VERSION ""

NS_ :

BS_:

BU_: BAP_Tester BedienDisp_vo BedienSG_hi CGS DDA Gateway Gateway_PAG GurtMikrofon OTA_FC ZR_High ZR_LIMU ZR_MIB_TOP_ab_Gen3 ZR_Standard

BO_ 870 Blinkmodi_02: 8 Gateway
 SG_ BM_ZV_auf : 12|1@1+ (1.0,0.0) [0.0|1] ""  ZR_High
 SG_ BM_ZV_zu : 13|1@1+ (1.0,0.0) [0.0|1] ""  ZR_High
 SG_ BM_DWA_ein : 14|1@1+ (1.0,0.0) [0.0|1] ""  ZR_High
 SG_ BM_DWA_Alarm : 15|1@1+ (1.0,0.0) [0.0|1] ""  ZR_High
 SG_ BM_Crash : 16|1@1+ (1.0,0.0) [0.0|1] ""  ZR_High
 SG_ BM_Panik : 17|1@1+ (1.0,0.0) [0.0|1] ""  ZR_High
 SG_ BM_Not_Bremsung : 18|1@1+ (1.0,0.0) [0.0|1] ""  ZR_High
 SG_ BM_GDO : 19|1@1+ (1.0,0.0) [0.0|1] ""  Vector__XXX
 SG_ BM_Warnblinken : 20|1@1+ (1.0,0.0) [0.0|1] ""  ZR_High
 SG_ BM_Taxi_Notalarm : 21|1@1+ (1.0,0.0) [0.0|1] ""  ZR_High
 SG_ BM_Telematik : 22|1@1+ (1.0,0.0) [0.0|1] ""  ZR_High
 SG_ BM_links : 23|1@1+ (1.0,0.0) [0.0|1] ""  ZR_High
 SG_ BM_rechts : 24|1@1+ (1.0,0.0) [0.0|1] ""  ZR_High
 SG_ Blinken_li_Fzg_Takt : 25|1@1+ (1.0,0.0) [0.0|1] ""  ZR_High
 SG_ Blinken_re_Fzg_Takt : 26|1@1+ (1.0,0.0) [0.0|1] ""  ZR_High
 SG_ Blinken_li_Kombi_Takt : 27|1@1+ (1.0,0.0) [0.0|1] ""  ZR_High,ZR_LIMU,ZR_MIB_TOP_ab_Gen3,ZR_Standard
 SG_ Blinken_re_Kombi_Takt : 28|1@1+ (1.0,0.0) [0.0|1] ""  ZR_High,ZR_LIMU,ZR_MIB_TOP_ab_Gen3,ZR_Standard
 SG_ BM_NBA_n_codiert_n_aktiv : 29|1@1+ (1.0,0.0) [0.0|1] ""  Vector__XXX
 SG_ BM_NBA_Status : 30|2@1+ (1.0,0.0) [0.0|3] ""  Vector__XXX
 SG_ BM_WBT_Beleuchtung : 32|1@1+ (1.0,0.0) [0.0|1] ""  ZR_High
 SG_ BM_HD_Oeffnung_angelernt : 33|1@1+ (1.0,0.0) [0.0|1] ""  Vector__XXX
 SG_ BM_Autobahn : 34|1@1+ (1.0,0.0) [0.0|1] ""  ZR_High,ZR_LIMU,ZR_MIB_TOP_ab_Gen3
 SG_ BM_Rollenmodus_Blinken : 35|1@1+ (1.0,0.0) [0.0|1] ""  Vector__XXX
 SG_ BM_Recas : 36|1@1+ (1.0,0.0) [0.0|1] ""  ZR_High
 SG_ BM_Wischblinken : 37|1@1+ (1.0,0.0) [0.0|1] ""  ZR_High
 SG_ BM_Telematik_Abbruchgrund : 38|6@1+ (1.0,0.0) [0.0|63] ""  Vector__XXX
 SG_ BM_PiloPa : 44|1@1+ (1.0,0.0) [0.0|1] ""  ZR_High
 SG_ DWA_Alarmquelle : 59|5@1+ (1.0,0.0) [0.0|31] ""  ZR_High

BO_ 299 GRA_ACC_01: 8 Gateway
 SG_ CHECKSUM : 0|8@1+ (1,0) [0|255] ""  Vector__XXX
 SG_ COUNTER : 8|4@1+ (1,0) [0|15] ""  Vector__XXX
 SG_ GRA_Hauptschalter : 12|1@1+ (1.0,0.0) [0.0|1] ""  ZR_High
 SG_ GRA_Abbrechen : 13|1@1+ (1.0,0.0) [0.0|1] ""  ZR_High
 SG_ GRA_Typ_Hauptschalter : 14|1@1+ (1.0,0.0) [0.0|1] ""  ZR_High
 SG_ GRA_Limiter : 15|1@1+ (1.0,0.0) [0.0|1] ""  ZR_High
 SG_ GRA_Tip_Setzen : 16|1@1+ (1.0,0.0) [0.0|1] ""  ZR_High
 SG_ GRA_Tip_Hoch : 17|1@1+ (1.0,0.0) [0.0|1] ""  ZR_High
 SG_ GRA_Tip_Runter : 18|1@1+ (1.0,0.0) [0.0|1] ""  ZR_High
 SG_ GRA_Tip_Wiederaufnahme : 19|1@1+ (1.0,0.0) [0.0|1] ""  ZR_High
 SG_ GRA_Verstellung_Zeitluecke : 20|2@1+ (1.0,0.0) [0.0|3] ""  ZR_High
 SG_ GRA_Codierung : 22|2@1+ (1.0,0.0) [0.0|3] ""  ZR_High
 SG_ GRA_Fehler : 24|1@1+ (1.0,0.0) [0.0|1] ""  ZR_High
 SG_ GRA_LIM_Taste_verfuegbar : 25|1@1+ (1.0,0.0) [0.0|1] ""  ZR_High
 SG_ GRA_Tip_Stufe_2 : 26|1@1+ (1.0,0.0) [0.0|1] ""  ZR_High
 SG_ GRA_Typ_Bedienteil : 27|3@1+ (1.0,0.0) [0.0|7] ""  ZR_High
 SG_ GRA_TravelAssist : 30|1@1+ (1.0,0.0) [0.0|1] ""  Vector__XXX
 SG_ GRA_reserveByte4 : 31|1@1+ (1.0,0.0) [0.0|1] ""  Vector__XXX
 SG_ GRA_reserveByte5 : 32|8@1+ (1.0,0.0) [0.0|255] ""  Vector__XXX
 SG_ GRA_reserveByte6 : 40|8@1+ (1.0,0.0) [0.0|255] ""  Vector__XXX
 SG_ GRA_reserveByte7 : 48|8@1+ (1.0,0.0) [0.0|255] ""  Vector__XXX
 SG_ GRA_reserveByte8 : 56|8@1+ (1.0,0.0) [0.0|255] ""  Vector__XXX

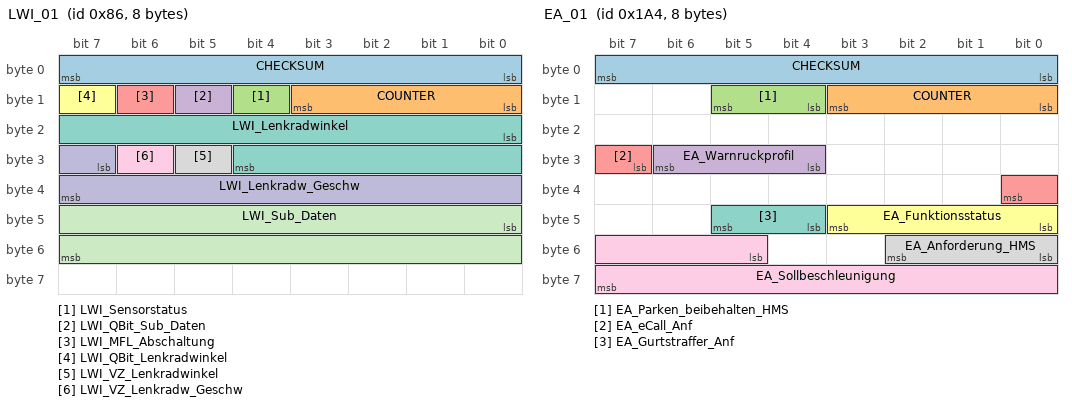
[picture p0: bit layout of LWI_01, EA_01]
BO_ 134 LWI_01: 8 Gateway
 SG_ CHECKSUM : 0|8@1+ (1,0) [0|255] ""  Vector__XXX
 SG_ COUNTER : 8|4@1+ (1,0) [0|15] ""  Vector__XXX
 SG_ LWI_Sensorstatus : 12|1@1+ (1.0,0.0) [0.0|1] ""  ZR_High,ZR_LIMU,ZR_MIB_TOP_ab_Gen3,ZR_Standard
 SG_ LWI_QBit_Sub_Daten : 13|1@1+ (1.0,0.0) [0.0|1] ""  ZR_High
 SG_ LWI_MFL_Abschaltung : 14|1@1+ (1.0,0.0) [0.0|1] ""  ZR_High
 SG_ LWI_QBit_Lenkradwinkel : 15|1@1+ (1.0,0.0) [0.0|1] ""  ZR_High,ZR_LIMU,ZR_MIB_TOP_ab_Gen3,ZR_Standard
 SG_ LWI_Lenkradwinkel : 16|13@1+ (0.1,0) [0.0|800.0] "Unit_DegreOfArc"  OTA_FC,ZR_High,ZR_LIMU,ZR_MIB_TOP_ab_Gen3,ZR_Standard
 SG_ LWI_VZ_Lenkradwinkel : 29|1@1+ (1.0,0.0) [0.0|1] ""  OTA_FC,ZR_High,ZR_LIMU,ZR_MIB_TOP_ab_Gen3,ZR_Standard
 SG_ LWI_VZ_Lenkradw_Geschw : 30|1@1+ (1.0,0.0) [0.0|1] ""  ZR_High
 SG_ LWI_Lenkradw_Geschw : 31|9@1+ (5,0) [0|2500] "Unit_DegreOfArcPerSecon"  OTA_FC,ZR_High
 SG_ LWI_Sub_Daten : 40|16@1+ (1,0) [0|65535] ""  Vector__XXX

BO_ 420 EA_01: 8 Gateway
 SG_ CHECKSUM : 0|8@1+ (1,0) [0|255] ""  Vector__XXX
 SG_ COUNTER : 8|4@1+ (1,0) [0|15] ""  Vector__XXX
 SG_ EA_Parken_beibehalten_HMS : 12|2@1+ (1.0,0.0) [0.0|3] ""  Vector__XXX
 SG_ EA_Warnruckprofil : 28|3@1+ (1.0,0.0) [0.0|7] ""  Vector__XXX
 SG_ EA_eCall_Anf : 31|2@1+ (1.0,0.0) [0.0|3] ""  ZR_High
 SG_ EA_Funktionsstatus : 40|4@1+ (1.0,0.0) [0.0|15] ""  ZR_High
 SG_ EA_Gurtstraffer_Anf : 44|2@1+ (1.0,0.0) [0.0|3] ""  Vector__XXX
 SG_ EA_Anforderung_HMS : 48|3@1+ (1.0,0.0) [0.0|7] ""  Vector__XXX
 SG_ EA_Sollbeschleunigung : 53|11@1+ (0.005,-7.22) [-7.220|3.005] "Unit_MeterPerSeconSquar"  Vector__XXX

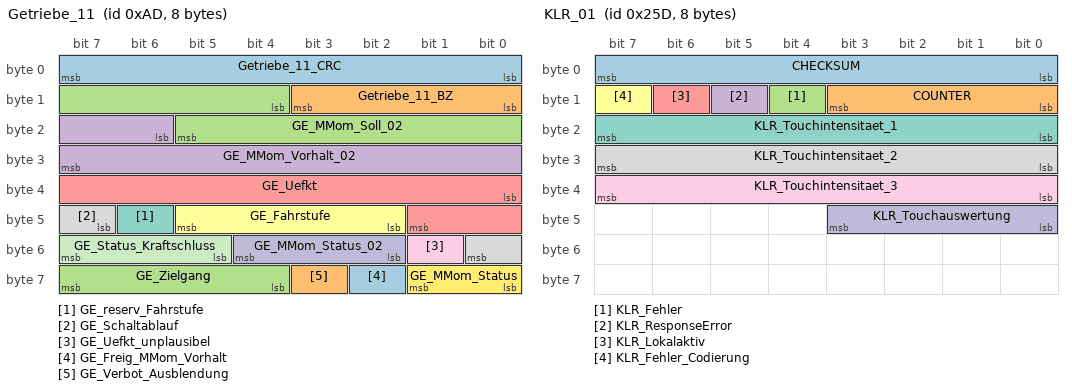
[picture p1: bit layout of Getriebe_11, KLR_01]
BO_ 173 Getriebe_11: 8 Gateway
 SG_ Getriebe_11_CRC : 0|8@1+ (1,0) [0|255] ""  Vector__XXX
 SG_ Getriebe_11_BZ : 8|4@1+ (1,0) [0|15] ""  Vector__XXX
 SG_ GE_MMom_Soll_02 : 12|10@1+ (1,-509) [-509|509] ""  Vector__XXX
 SG_ GE_MMom_Vorhalt_02 : 22|10@1+ (1,-509) [-509|509] ""  Vector__XXX
 SG_ GE_Uefkt : 32|10@1+ (0.1,0) [0.0|102.2] ""  Vector__XXX
 SG_ GE_Fahrstufe : 42|4@1+ (1.0,0.0) [0.0|15] ""  DDA,OTA_FC,ZR_High,ZR_LIMU,ZR_MIB_TOP_ab_Gen3
 SG_ GE_reserv_Fahrstufe : 46|1@1+ (1,0) [0|1] ""  Vector__XXX
 SG_ GE_Schaltablauf : 47|2@1+ (1.0,0.0) [0.0|3] ""  Vector__XXX
 SG_ GE_Uefkt_unplausibel : 49|1@1+ (1.0,0.0) [0.0|1] ""  Vector__XXX
 SG_ GE_MMom_Status_02 : 50|3@1+ (1.0,0.0) [0.0|7] ""  Vector__XXX
 SG_ GE_Status_Kraftschluss : 53|3@1+ (1.0,0.0) [0.0|7] ""  Vector__XXX
 SG_ GE_MMom_Status : 56|2@1+ (1.0,0.0) [0.0|3] ""  Vector__XXX
 SG_ GE_Freig_MMom_Vorhalt : 58|1@1+ (1.0,0.0) [0.0|1] ""  Vector__XXX
 SG_ GE_Verbot_Ausblendung : 59|1@1+ (1.0,0.0) [0.0|1] ""  Vector__XXX
 SG_ GE_Zielgang : 60|4@1+ (1.0,0.0) [0.0|15] ""  OTA_FC,ZR_High

BO_ 1411 ZV_02: 8 Gateway
 SG_ BCM_FH_Freigabe : 12|1@1+ (1.0,0.0) [0.0|1] ""  BedienDisp_vo
 SG_ BCM_Komfortfkt_Freigabe : 13|1@1+ (1.0,0.0) [0.0|1] ""  Vector__XXX
 SG_ BCM_HSK_Freigabe : 14|1@1+ (1.0,0.0) [0.0|1] ""  Vector__XXX
 SG_ BCM_Verdeck_Freigabe : 15|1@1+ (1.0,0.0) [0.0|1] ""  ZR_High
 SG_ ZV_verriegelt_intern_ist : 16|1@1+ (1.0,0.0) [0.0|1] ""  DDA,OTA_FC,ZR_High
 SG_ ZV_verriegelt_extern_ist : 17|1@1+ (1.0,0.0) [0.0|1] ""  DDA,OTA_FC,ZR_High
 SG_ ZV_verriegelt_intern_soll : 18|1@1+ (1.0,0.0) [0.0|1] ""  ZR_High
 SG_ ZV_verriegelt_extern_soll : 19|1@1+ (1.0,0.0) [0.0|1] ""  OTA_FC,ZR_High,ZR_LIMU,ZR_MIB_TOP_ab_Gen3,ZR_Standard
 SG_ ZV_gesafet_extern_ist : 20|1@1+ (1.0,0.0) [0.0|1] ""  ZR_High
 SG_ ZV_gesafet_extern_soll : 21|1@1+ (1.0,0.0) [0.0|1] ""  ZR_High,ZR_LIMU,ZR_MIB_TOP_ab_Gen3
 SG_ ZV_Einzeltuerentriegelung : 22|1@1+ (1.0,0.0) [0.0|1] ""  Vector__XXX
 SG_ ZV_Heckeinzelentriegelung : 23|1@1+ (1.0,0.0) [0.0|1] ""  Vector__XXX
 SG_ ZV_FT_offen : 24|1@1+ (1.0,0.0) [0.0|1] ""  DDA,OTA_FC,ZR_High,ZR_LIMU,ZR_MIB_TOP_ab_Gen3,ZR_Standard
 SG_ ZV_BT_offen : 25|1@1+ (1.0,0.0) [0.0|1] ""  DDA,OTA_FC,ZR_High,ZR_LIMU,ZR_MIB_TOP_ab_Gen3,ZR_Standard
 SG_ ZV_HFS_offen : 26|1@1+ (1.0,0.0) [0.0|1] ""  DDA,OTA_FC,ZR_High,ZR_LIMU,ZR_MIB_TOP_ab_Gen3,ZR_Standard
 SG_ ZV_HBFS_offen : 27|1@1+ (1.0,0.0) [0.0|1] ""  DDA,OTA_FC,ZR_High,ZR_LIMU,ZR_MIB_TOP_ab_Gen3,ZR_Standard
 SG_ ZV_HD_offen : 28|1@1+ (1.0,0.0) [0.0|1] ""  DDA,OTA_FC,ZR_High,ZR_LIMU,ZR_MIB_TOP_ab_Gen3,ZR_Standard
 SG_ ZV_HS_offen : 29|1@1+ (1.0,0.0) [0.0|1] ""  OTA_FC,ZR_High
 SG_ IRUE_aktiv : 30|1@1+ (1.0,0.0) [0.0|1] ""  ZR_High
 SG_ DWA_aktiv : 31|1@1+ (1.0,0.0) [0.0|1] ""  ZR_High
 SG_ HD_Hauptraste : 32|1@1+ (1.0,0.0) [0.0|1] ""  OTA_FC,ZR_High
 SG_ HD_Vorraste : 33|1@1+ (1.0,0.0) [0.0|1] ""  OTA_FC,ZR_High
 SG_ FFB_CarFinder : 38|1@1+ (1.0,0.0) [0.0|1] ""  Vector__XXX
 SG_ FFB_Komfortoeffnen : 39|1@1+ (1.0,0.0) [0.0|1] ""  Vector__XXX
 SG_ FFB_Komfortschliessen : 40|1@1+ (1.0,0.0) [0.0|1] ""  Vector__XXX
 SG_ ZV_Schluessel_Zugang : 42|4@1+ (1.0,0.0) [0.0|15] ""  ZR_High
 SG_ ZV_SafeFunktion_aktiv : 46|1@1+ (1.0,0.0) [0.0|1] ""  ZR_High
 SG_ FBS_Warn_Schluessel_Batt : 47|1@1+ (1.0,0.0) [0.0|1] ""  ZR_High
 SG_ ZV_Oeffnungsmodus : 48|2@1+ (1.0,0.0) [0.0|3] ""  Vector__XXX
 SG_ HFS_verriegelt : 50|1@1+ (1.0,0.0) [0.0|1] ""  OTA_FC
 SG_ HFS_gesafet : 51|1@1+ (1.0,0.0) [0.0|1] ""  Vector__XXX
 SG_ HBFS_verriegelt : 52|1@1+ (1.0,0.0) [0.0|1] ""  OTA_FC
 SG_ HBFS_gesafet : 53|1@1+ (1.0,0.0) [0.0|1] ""  Vector__XXX
 SG_ ZV_ist_Zustand_verfuegbar : 54|1@1+ (1.0,0.0) [0.0|1] ""  OTA_FC,ZR_High
 SG_ IRUE_Taster_Fkts_LED : 55|1@1+ (1.0,0.0) [0.0|1] ""  ZR_High
 SG_ ZV_Tankklappe_offen : 56|1@1+ (1.0,0.0) [0.0|1] ""  ZR_High
 SG_ ZV_Rollo_auf : 57|1@1+ (1.0,0.0) [0.0|1] ""  ZR_High
 SG_ ZV_Rollo_zu : 58|1@1+ (1.0,0.0) [0.0|1] ""  ZR_High
 SG_ ZV_SAD_auf : 59|1@1+ (1.0,0.0) [0.0|1] ""  ZR_High
 SG_ ZV_SAD_zu : 60|1@1+ (1.0,0.0) [0.0|1] ""  ZR_High
 SG_ BCM_Tankklappensteller_Fehler : 61|1@1+ (1.0,0.0) [0.0|1] ""  ZR_High
 SG_ ZV_verriegelt_soll : 62|2@1+ (1.0,0.0) [0.0|3] ""  Vector__XXX

BO_ 1312 Airbag_02: 8 Gateway
 SG_ Airbag_02_CRC : 0|8@1+ (1,0) [0|255] ""  Vector__XXX
 SG_ Airbag_02_BZ : 8|4@1+ (1,0) [0|15] ""  Vector__XXX
 SG_ LoGeWa_Event_Kombiwarnung : 12|4@1+ (1.0,0.0) [0.0|15] ""  ZR_High
 SG_ AB_Anforderung_eCall : 16|1@1+ (1.0,0.0) [0.0|1] ""  ZR_High
 SG_ AB_Anprall_Seite_Beifahrer : 17|1@1+ (1.0,0.0) [0.0|1] ""  Vector__XXX
 SG_ AB_Anprall_Rollover : 18|1@1+ (1.0,0.0) [0.0|1] ""  Vector__XXX
 SG_ AB_Anprall_FGS : 19|1@1+ (1.0,0.0) [0.0|1] ""  Vector__XXX
 SG_ AB_Anprall_Front_Beifahrer : 20|1@1+ (1.0,0.0) [0.0|1] ""  Vector__XXX
 SG_ AB_Anprall_Front_Fahrer : 21|1@1+ (1.0,0.0) [0.0|1] ""  Vector__XXX
 SG_ AB_Anprall_Heck_Beifahrer : 22|1@1+ (1.0,0.0) [0.0|1] ""  Vector__XXX
 SG_ AB_Anprall_Heck_Fahrer : 23|1@1+ (1.0,0.0) [0.0|1] ""  Vector__XXX
 SG_ AB_Wickelklappung_Reihe2_MI : 24|2@1+ (1.0,0.0) [0.0|3] ""  Vector__XXX
 SG_ AB_Belegung_VB : 26|2@1+ (1.0,0.0) [0.0|3] ""  BedienSG_hi,GurtMikrofon,ZR_High,ZR_LIMU,ZR_MIB_TOP_ab_Gen3
 SG_ AB_Abschaltanf_SIH_BF : 28|1@1+ (1.0,0.0) [0.0|1] ""  ZR_High
 SG_ AB_Anprall_Seite_Fahrer : 29|1@1+ (1.0,0.0) [0.0|1] ""  Vector__XXX
 SG_ SC_PAO_Schriftzug_Anf : 30|2@1+ (1.0,0.0) [0.0|3] ""  ZR_High
 SG_ SC_PAO_ON_Anf : 32|2@1+ (1.0,0.0) [0.0|3] ""  ZR_High
 SG_ SC_PAO_OFF_Anf : 34|2@1+ (1.0,0.0) [0.0|3] ""  ZR_High
 SG_ AB_Crashschwere : 36|3@1+ (1.0,0.0) [0.0|7] ""  Vector__XXX
 SG_ AB_Anforderung_USM : 39|1@1+ (1.0,0.0) [0.0|1] ""  ZR_Standard
 SG_ AB_Gurtschloss_FA : 40|2@1+ (1.0,0.0) [0.0|3] ""  BedienSG_hi,GurtMikrofon,ZR_High
 SG_ AB_Gurtschloss_BF : 42|2@1+ (1.0,0.0) [0.0|3] ""  BedienSG_hi,GurtMikrofon,ZR_High,ZR_LIMU,ZR_MIB_TOP_ab_Gen3
 SG_ AB_Gurtschloss_Reihe2_FA : 44|2@1+ (1.0,0.0) [0.0|3] ""  BedienSG_hi,ZR_High,ZR_LIMU,ZR_MIB_TOP_ab_Gen3
 SG_ AB_Gurtschloss_Reihe2_MI : 46|2@1+ (1.0,0.0) [0.0|3] ""  BedienSG_hi,ZR_High,ZR_LIMU,ZR_MIB_TOP_ab_Gen3
 SG_ AB_Gurtschloss_Reihe2_BF : 48|2@1+ (1.0,0.0) [0.0|3] ""  BedienSG_hi,ZR_High,ZR_LIMU,ZR_MIB_TOP_ab_Gen3
 SG_ AB_Gurtschloss_Reihe3_FA : 50|2@1+ (1.0,0.0) [0.0|3] ""  BedienSG_hi,ZR_High
 SG_ AB_Gurtschloss_Reihe3_MI : 52|2@1+ (1.0,0.0) [0.0|3] ""  BedienSG_hi,ZR_High
 SG_ AB_Gurtschloss_Reihe3_BF : 54|2@1+ (1.0,0.0) [0.0|3] ""  BedienSG_hi,ZR_High
 SG_ AB_Sitzpos_Sens_FA : 56|2@1+ (1.0,0.0) [0.0|3] ""  ZR_High
 SG_ AB_Sitzpos_Sens_BF : 58|2@1+ (1.0,0.0) [0.0|3] ""  ZR_High
 SG_ AB_Wickelklappung_Reihe2_BF : 60|2@1+ (1.0,0.0) [0.0|3] ""  ZR_High
 SG_ AB_Wickelklappung_Reihe2_FA : 62|2@1+ (1.0,0.0) [0.0|3] ""  ZR_High

BO_ 605 KLR_01: 8 Gateway
 SG_ CHECKSUM : 0|8@1+ (1,0) [0|255] ""  Vector__XXX
 SG_ COUNTER : 8|4@1+ (1,0) [0|15] ""  Vector__XXX
 SG_ KLR_Fehler : 12|1@1+ (1.0,0.0) [0.0|1] ""  Vector__XXX
 SG_ KLR_ResponseError : 13|1@1+ (1.0,0.0) [0.0|1] ""  Vector__XXX
 SG_ KLR_Lokalaktiv : 14|1@1+ (1.0,0.0) [0.0|1] ""  Vector__XXX
 SG_ KLR_Fehler_Codierung : 15|1@1+ (1.0,0.0) [0.0|1] ""  Vector__XXX
 SG_ KLR_Touchintensitaet_1 : 16|8@1+ (1,0) [0|250] "Unit_None"  Vector__XXX
 SG_ KLR_Touchintensitaet_2 : 24|8@1+ (1,0) [0|250] "Unit_None"  Vector__XXX
 SG_ KLR_Touchintensitaet_3 : 32|8@1+ (1,0) [0|250] "Unit_None"  Vector__XXX
 SG_ KLR_Touchauswertung : 40|4@1+ (1.0,0.0) [0.0|15] ""  ZR_High

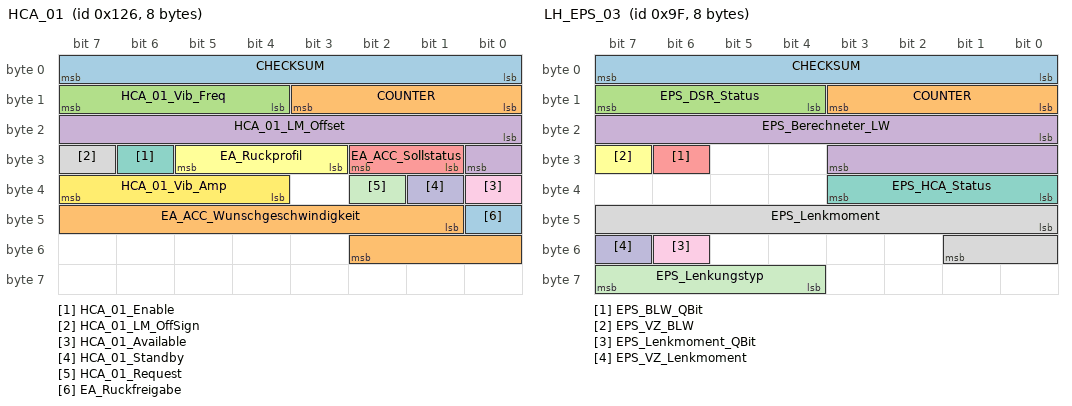
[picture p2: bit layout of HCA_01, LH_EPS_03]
BO_ 294 HCA_01: 8 Frontsensorik
 SG_ CHECKSUM : 0|8@1+ (1,0) [0|255] "" Vector__XXX
 SG_ COUNTER : 8|4@1+ (1,0) [0|15] "" Vector__XXX
 SG_ HCA_01_Vib_Freq : 12|4@1+ (1,15) [15|30] "Unit_Hertz" Vector__XXX
 SG_ HCA_01_LM_Offset : 16|9@1+ (1,0) [0|511] "Unit_centiNewtoMeter" Vector__XXX
 SG_ EA_ACC_Sollstatus : 25|2@1+ (1,0) [0|3] ""  Frontradar
 SG_ EA_Ruckprofil : 27|3@1+ (1,0) [0|7] "" Vector__XXX
 SG_ HCA_01_Enable : 30|1@1+ (1,0) [0|1] "" Vector__XXX
 SG_ HCA_01_LM_OffSign : 31|1@1+ (1,0) [0|1] "" Vector__XXX
 SG_ HCA_01_Available : 32|1@1+ (1,0) [0|1] "" Vector__XXX
 SG_ HCA_01_Standby : 33|1@1+ (1,0) [0|1] "" Vector__XXX
 SG_ HCA_01_Request : 34|1@1+ (1,0) [0|1] "" Vector__XXX
 SG_ HCA_01_Vib_Amp : 36|4@1+ (0.2,0) [0|3] "Unit_NewtoMeter" Vector__XXX
 SG_ EA_Ruckfreigabe : 40|1@1+ (1,0) [0|1] "" Vector__XXX
 SG_ EA_ACC_Wunschgeschwindigkeit : 41|10@1+ (0.32,0) [0|327.04] "Unit_KiloMeterPerHour"  Frontradar

BO_ 159 LH_EPS_03: 8 XXX
 SG_ CHECKSUM : 0|8@1+ (1,0) [0|255] ""  XXX
 SG_ COUNTER : 8|4@1+ (1,0) [0|15] ""  XXX
 SG_ EPS_DSR_Status : 12|4@1+ (1,0) [0|15] ""  XXX
 SG_ EPS_Berechneter_LW : 16|12@1+ (0.15,0) [0|613.95] "Unit_DegreOfArc"  XXX
 SG_ EPS_BLW_QBit : 30|1@1+ (1,0) [0|1] ""  XXX
 SG_ EPS_VZ_BLW : 31|1@1+ (1,0) [0|1] ""  XXX
 SG_ EPS_HCA_Status : 32|4@1+ (1,0) [0|15] ""  XXX
 SG_ EPS_Lenkmoment : 40|10@1+ (1,0) [0|8] "Unit_centiNewtoMeter"  XXX
 SG_ EPS_Lenkmoment_QBit : 54|1@1+ (1,0) [0|1] ""  XXX
 SG_ EPS_VZ_Lenkmoment : 55|1@1+ (1,0) [0|1] ""  XXX
 SG_ EPS_Lenkungstyp : 60|4@1+ (1,0) [0|15] ""  XXX

BO_ 919 LDW_02: 8 XXX
 SG_ LDW_Gong : 12|2@1+ (1,0) [0|3] ""  XXX
 SG_ LDW_SW_Warnung_links : 14|1@1+ (1,0) [0|1] ""  XXX
 SG_ LDW_SW_Warnung_rechts : 15|1@1+ (1,0) [0|1] ""  XXX
 SG_ LDW_Texte : 16|4@1+ (1,0) [0|15] ""  XXX
 SG_ LDW_Seite_DLCTLC : 20|1@1+ (1,0) [0|1] ""  XXX
 SG_ LDW_Lernmodus : 21|3@1+ (1,0) [0|7] ""  XXX
 SG_ LDW_Anlaufsp_VLR : 24|4@1+ (1,0) [0|15] ""  XXX
 SG_ LDW_Vib_Amp_VLR : 28|4@1+ (1,0) [0|15] ""  XXX
 SG_ LDW_Anlaufzeit_VLR : 32|4@1+ (1,0) [0|15] ""  XXX
 SG_ LDW_Lernmodus_rechts : 36|2@1+ (1,0) [0|3] ""  XXX
 SG_ LDW_Lernmodus_links : 38|2@1+ (1,0) [0|3] ""  XXX
 SG_ LDW_DLC : 40|8@1+ (0.01,-1.25) [-1.25|1.25] "Unit_Meter"  XXX
 SG_ LDW_TLC : 48|5@1+ (0.1,0) [0|3] "Unit_Secon"  XXX
 SG_ LDW_Warnung_links : 56|1@1+ (1,0) [0|1] ""  XXX
 SG_ LDW_Warnung_rechts : 57|1@1+ (1,0) [0|1] ""  XXX
 SG_ LDW_Codierinfo_fuer_VLR : 58|2@1+ (1,0) [0|3] ""  XXX
 SG_ LDW_Frontscheibenheizung_aktiv : 60|1@1+ (1,0) [0|1] ""  XXX
 SG_ LDW_Status_LED_gelb : 61|1@1+ (1,0) [0|1] ""  XXX
 SG_ LDW_Status_LED_gruen : 62|1@1+ (1,0) [0|1] ""  XXX
 SG_ LDW_KD_Fehler : 63|1@1+ (1,0) [0|1] ""  XXX

BO_ 977 TSG_BT_01: 8 Gateway
 SG_ BT_Tuer_geoeffnet : 0|1@1+ (1.0,0.0) [0.0|1] ""  OTA_FC,ZR_High,ZR_LIMU,ZR_MIB_TOP_ab_Gen3,ZR_Standard
 SG_ BT_verriegelt : 1|1@1+ (1.0,0.0) [0.0|1] ""  OTA_FC,ZR_High
 SG_ BT_gesafet : 2|1@1+ (1.0,0.0) [0.0|1] ""  ZR_High
 SG_ BT_Schluesselschalter_auf : 3|1@1+ (1.0,0.0) [0.0|1] ""  ZR_High
 SG_ BT_Schluesselschalter_zu : 4|1@1+ (1.0,0.0) [0.0|1] ""  ZR_High
 SG_ BT_Unlock_Taster : 5|1@1+ (1.0,0.0) [0.0|1] ""  ZR_High
 SG_ BT_Lock_Taster : 6|1@1+ (1.0,0.0) [0.0|1] ""  ZR_High
 SG_ BT_Sperrklinke : 7|1@1+ (1.0,0.0) [0.0|1] ""  Vector__XXX
 SG_ BT_TAG_betaetigt : 8|1@1+ (1.0,0.0) [0.0|1] ""  ZR_High
 SG_ BT_TIG_betaetigt : 9|1@1+ (1.0,0.0) [0.0|1] ""  ZR_High
 SG_ BT_EC_Spiegel_Helligkeit : 10|5@1+ (3.125,0) [0.000|96.875] "Unit_PerCent"  OTA_FC,ZR_High
 SG_ BT_Sp_Heizung_Anf : 15|1@1+ (100,0) [0|100] "Unit_PerCent"  ZR_High
 SG_ BT_Tuer_Status : 16|2@1+ (1.0,0.0) [0.0|3] ""  OTA_FC,ZR_High
 SG_ BT_TSG_hinten_verbaut : 18|1@1+ (1.0,0.0) [0.0|1] ""  ZR_High
 SG_ BT_Sp_Blk_def : 19|1@1+ (1.0,0.0) [0.0|1] ""  ZR_High
 SG_ BT_FH_S_ManHoch : 20|1@1+ (1.0,0.0) [0.0|1] ""  ZR_High
 SG_ BT_FH_S_AutoHoch : 21|1@1+ (1.0,0.0) [0.0|1] ""  ZR_High
 SG_ BT_FH_S_ManTief : 22|1@1+ (1.0,0.0) [0.0|1] ""  ZR_High
 SG_ BT_FH_S_AutoTief : 23|1@1+ (1.0,0.0) [0.0|1] ""  ZR_High
 SG_ BT_FH_Oeffnung : 24|8@1+ (0.5,0) [0.0|100.0] "Unit_PerCent"  DDA,OTA_FC,ZR_High,ZR_LIMU,ZR_MIB_TOP_ab_Gen3,ZR_Standard
 SG_ BT_FH_Bew_hoch : 32|1@1+ (1.0,0.0) [0.0|1] ""  ZR_High
 SG_ BT_FH_Bew_tief : 33|1@1+ (1.0,0.0) [0.0|1] ""  ZR_High
 SG_ BT_FH_Fang : 34|1@1+ (1.0,0.0) [0.0|1] ""  ZR_High
 SG_ BT_FH_Block : 35|1@1+ (1.0,0.0) [0.0|1] ""  ZR_High
 SG_ BT_FH_Thermo : 36|1@1+ (1.0,0.0) [0.0|1] ""  ZR_High
 SG_ BT_UEKB_aktiviert : 37|1@1+ (1.0,0.0) [0.0|1] ""  Vector__XXX
 SG_ BT_Kisi_Fehler : 38|1@1+ (1.0,0.0) [0.0|1] ""  ZR_High
 SG_ BT_FH_normiert : 39|1@1+ (1.0,0.0) [0.0|1] ""  Vector__XXX
 SG_ BT_Schliesstaster : 40|1@1+ (1.0,0.0) [0.0|1] ""  ZR_High
 SG_ BT_Zuziehhilfe_aktiv : 41|1@1+ (1.0,0.0) [0.0|1] ""  OTA_FC,ZR_High
 SG_ BT_SP_ausgerastet : 42|1@1+ (1.0,0.0) [0.0|1] ""  ZR_High
 SG_ BT_SP_lr_aktiv : 43|1@1+ (1.0,0.0) [0.0|1] ""  ZR_High
 SG_ BT_SP_ht_aktiv : 44|1@1+ (1.0,0.0) [0.0|1] ""  ZR_High
 SG_ BT_SP_Heizung_aktiv : 45|1@1+ (1.0,0.0) [0.0|1] ""  Vector__XXX
 SG_ BT_Oben_Block_erw : 46|1@1+ (1.0,0.0) [0.0|1] ""  ZR_High
 SG_ BT_Unten_Block_erw : 47|1@1+ (1.0,0.0) [0.0|1] ""  ZR_High
 SG_ BT_Tuer_Status_QBit : 48|1@1+ (1.0,0.0) [0.0|1] ""  Vector__XXX
 SG_ BFS_Status_eTAG : 49|2@1+ (1.0,0.0) [0.0|3] ""  Vector__XXX
 SG_ BT_TCR_Mode_aktiv : 51|1@1+ (1.0,0.0) [0.0|1] ""  Vector__XXX
 SG_ BT_SP_Heizung_Status : 55|1@1+ (1.0,0.0) [0.0|1] ""  OTA_FC,ZR_High
 SG_ ASW_Warnung_aktiv_BFS : 56|1@1+ (1.0,0.0) [0.0|1] ""  ZR_High
 SG_ BT_FH_Pos_oben : 57|1@1+ (1.0,0.0) [0.0|1] ""  OTA_FC,ZR_High
 SG_ BT_Tuerschloss_defekt : 58|1@1+ (1.0,0.0) [0.0|1] ""  ZR_High
 SG_ BT_Tueroeffnen_Warnung : 59|1@1+ (1.0,0.0) [0.0|1] ""  Vector__XXX
 SG_ BT_Lock_Taster_inv : 60|1@1+ (1.0,0.0) [0.0|1] ""  ZR_High
 SG_ BT_Schluesselschalter_zu_inv : 61|1@1+ (1.0,0.0) [0.0|1] ""  ZR_High
 SG_ BT_SWA_HMI_defekt : 62|1@1+ (1.0,0.0) [0.0|1] ""  ZR_High
 SG_ BT_ASW_HMI_defekt : 63|1@1+ (1.0,0.0) [0.0|1] ""  ZR_High

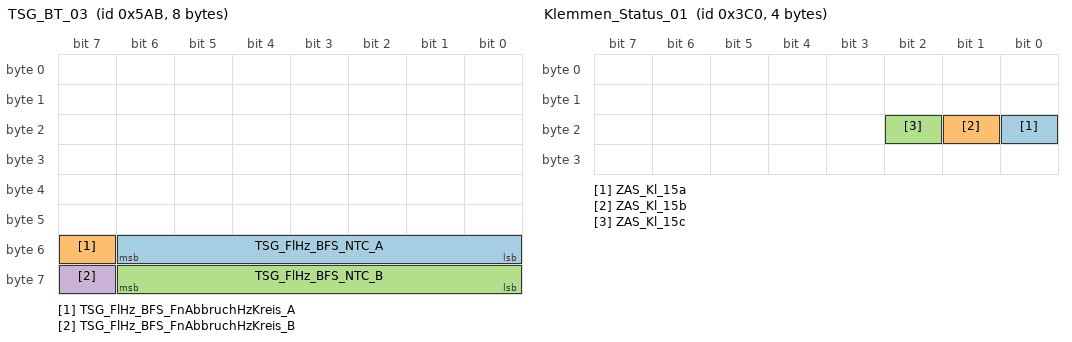
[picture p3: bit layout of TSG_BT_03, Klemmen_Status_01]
BO_ 1451 TSG_BT_03: 8 Gateway
 SG_ TSG_FlHz_BFS_NTC_A : 48|7@1+ (1,-40) [-40|80] "Unit_DegreCelsi"  ZR_High
 SG_ TSG_FlHz_BFS_FnAbbruchHzKreis_A : 55|1@1+ (1.0,0.0) [0.0|1] ""  ZR_High
 SG_ TSG_FlHz_BFS_NTC_B : 56|7@1+ (1,-40) [-40|80] "Unit_DegreCelsi"  ZR_High
 SG_ TSG_FlHz_BFS_FnAbbruchHzKreis_B : 63|1@1+ (1.0,0.0) [0.0|1] ""  ZR_High

BO_ 976 TSG_FT_01: 8 Gateway
 SG_ FT_Tuer_geoeffnet : 0|1@1+ (1.0,0.0) [0.0|1] ""  BedienDisp_vo,OTA_FC,ZR_High,ZR_LIMU,ZR_MIB_TOP_ab_Gen3,ZR_Standard
 SG_ FT_verriegelt : 1|1@1+ (1.0,0.0) [0.0|1] ""  OTA_FC,ZR_High
 SG_ FT_gesafet : 2|1@1+ (1.0,0.0) [0.0|1] ""  ZR_High
 SG_ FT_Schluesselschalter_auf : 3|1@1+ (1.0,0.0) [0.0|1] ""  ZR_High
 SG_ FT_Schluesselschalter_zu : 4|1@1+ (1.0,0.0) [0.0|1] ""  ZR_High
 SG_ FT_Unlock_Taster : 5|1@1+ (1.0,0.0) [0.0|1] ""  ZR_High
 SG_ FT_Lock_Taster : 6|1@1+ (1.0,0.0) [0.0|1] ""  ZR_High
 SG_ FT_Sperrklinke : 7|1@1+ (1.0,0.0) [0.0|1] ""  ZR_High
 SG_ FT_TAG_betaetigt : 8|1@1+ (1.0,0.0) [0.0|1] ""  ZR_High
 SG_ FT_TIG_betaetigt : 9|1@1+ (1.0,0.0) [0.0|1] ""  ZR_High
 SG_ FT_IRUE_Taste : 10|1@1+ (1.0,0.0) [0.0|1] ""  ZR_High
 SG_ FT_HD_Taste : 11|1@1+ (1.0,0.0) [0.0|1] ""  OTA_FC,ZR_High
 SG_ FT_TD_Taste_Fehler : 12|1@1+ (1.0,0.0) [0.0|1] ""  ZR_High
 SG_ FT_TD_Taste : 13|1@1+ (1.0,0.0) [0.0|1] ""  OTA_FC,ZR_High
 SG_ SSR_Temp_Freigabe : 14|1@1+ (1.0,0.0) [0.0|1] ""  Vector__XXX
 SG_ FT_Sp_Heizung_Anf : 15|1@1+ (100,0) [0|100] "Unit_PerCent"  OTA_FC,ZR_High
 SG_ FT_HD_Taste_2 : 16|1@1+ (1.0,0.0) [0.0|1] ""  ZR_High
 SG_ FT_TSG_hinten_verbaut : 18|1@1+ (1.0,0.0) [0.0|1] ""  ZR_High
 SG_ FT_Sp_Blk_def : 19|1@1+ (1.0,0.0) [0.0|1] ""  ZR_High
 SG_ FT_FH_S_ManHoch : 20|1@1+ (1.0,0.0) [0.0|1] ""  ZR_High
 SG_ FT_FH_S_AutoHoch : 21|1@1+ (1.0,0.0) [0.0|1] ""  ZR_High
 SG_ FT_FH_S_ManTief : 22|1@1+ (1.0,0.0) [0.0|1] ""  ZR_High
 SG_ FT_FH_S_AutoTief : 23|1@1+ (1.0,0.0) [0.0|1] ""  ZR_High
 SG_ FT_FH_Oeffnung : 24|8@1+ (0.5,0) [0.0|100.0] "Unit_PerCent"  DDA,OTA_FC,ZR_High,ZR_LIMU,ZR_MIB_TOP_ab_Gen3,ZR_Standard
 SG_ FT_FH_Bew_hoch : 32|1@1+ (1.0,0.0) [0.0|1] ""  ZR_High
 SG_ FT_FH_Bew_tief : 33|1@1+ (1.0,0.0) [0.0|1] ""  ZR_High
 SG_ FT_FH_Fang : 34|1@1+ (1.0,0.0) [0.0|1] ""  ZR_High
 SG_ FT_FH_Block : 35|1@1+ (1.0,0.0) [0.0|1] ""  ZR_High
 SG_ FT_FH_Thermo : 36|1@1+ (1.0,0.0) [0.0|1] ""  ZR_High
 SG_ FT_UEKB_aktiviert : 37|1@1+ (1.0,0.0) [0.0|1] ""  ZR_High
 SG_ ASW_HMI_defekt : 38|1@1+ (1.0,0.0) [0.0|1] ""  ZR_High
 SG_ FT_FH_normiert : 39|1@1+ (1.0,0.0) [0.0|1] ""  Vector__XXX
 SG_ FT_Schliesstaster : 40|1@1+ (1.0,0.0) [0.0|1] ""  ZR_High
 SG_ FT_Zuziehhilfe_aktiv : 41|1@1+ (1.0,0.0) [0.0|1] ""  OTA_FC,ZR_High
 SG_ FT_SP_ausgerastet : 42|1@1+ (1.0,0.0) [0.0|1] ""  ZR_High
 SG_ FT_SP_lr_aktiv : 43|1@1+ (1.0,0.0) [0.0|1] ""  OTA_FC,ZR_High
 SG_ FT_SP_ht_aktiv : 44|1@1+ (1.0,0.0) [0.0|1] ""  OTA_FC,ZR_High
 SG_ ASW_wakeup : 45|1@1+ (1.0,0.0) [0.0|1] ""  Vector__XXX
 SG_ FT_Oben_Block_erw : 46|1@1+ (1.0,0.0) [0.0|1] ""  ZR_High
 SG_ FT_Unten_Block_erw : 47|1@1+ (1.0,0.0) [0.0|1] ""  ZR_High
 SG_ FT_Kisi_li_aktiv : 48|1@1+ (1.0,0.0) [0.0|1] ""  BedienDisp_vo,BedienSG_hi,ZR_High,ZR_LIMU,ZR_MIB_TOP_ab_Gen3,ZR_Standard
 SG_ FT_Kisi_re_aktiv : 49|1@1+ (1.0,0.0) [0.0|1] ""  BedienDisp_vo,BedienSG_hi,ZR_High,ZR_LIMU,ZR_MIB_TOP_ab_Gen3,ZR_Standard
 SG_ FT_Kisi_Taster_li : 50|1@1+ (1.0,0.0) [0.0|1] ""  ZR_High
 SG_ FT_Kisi_Taster_re : 51|1@1+ (1.0,0.0) [0.0|1] ""  ZR_High
 SG_ FT_BFS_Fond_Freigabe : 52|1@1+ (1.0,0.0) [0.0|1] ""  ZR_High
 SG_ FT_Kisi_Fehler : 53|1@1+ (1.0,0.0) [0.0|1] ""  BedienSG_hi,ZR_High
 SG_ FT_Daemmglas : 54|1@1+ (1.0,0.0) [0.0|1] ""  ZR_High
 SG_ FT_SP_Heizung_Status : 55|1@1+ (1.0,0.0) [0.0|1] ""  OTA_FC,ZR_High
 SG_ ASW_Warnung_aktiv_FS : 56|1@1+ (1.0,0.0) [0.0|1] ""  ZR_High
 SG_ FT_FH_Pos_oben : 57|1@1+ (1.0,0.0) [0.0|1] ""  OTA_FC,ZR_High
 SG_ FT_Tuerschloss_defekt : 58|1@1+ (1.0,0.0) [0.0|1] ""  ZR_High
 SG_ FT_SWA_Taster : 59|1@1+ (1.0,0.0) [0.0|1] ""  ZR_High
 SG_ SWA_HMI_Diagnose : 60|2@1+ (1.0,0.0) [0.0|3] ""  ZR_High
 SG_ FS_Status_eTAG : 62|2@1+ (1.0,0.0) [0.0|3] ""  Vector__XXX

BO_ 975 TSG_HBFS_01: 8 Gateway
 SG_ HBFS_Tuer_geoeffnet : 0|1@1+ (1.0,0.0) [0.0|1] ""  OTA_FC,ZR_High,ZR_LIMU,ZR_MIB_TOP_ab_Gen3,ZR_Standard
 SG_ HBFS_verriegelt : 1|1@1+ (1.0,0.0) [0.0|1] ""  ZR_High
 SG_ HBFS_gesafet : 2|1@1+ (1.0,0.0) [0.0|1] ""  ZR_High
 SG_ HBFS_Heckrollotaster_betaetigt : 3|1@1+ (1.0,0.0) [0.0|1] ""  ZR_High
 SG_ HBFS_Tuerschloss_defekt : 4|1@1+ (1.0,0.0) [0.0|1] ""  ZR_High
 SG_ HBFS_Unlock_Taster : 5|1@1+ (1.0,0.0) [0.0|1] ""  ZR_High
 SG_ HBFS_Lock_Taster : 6|1@1+ (1.0,0.0) [0.0|1] ""  ZR_High
 SG_ HBFS_Sperrklinke : 7|1@1+ (1.0,0.0) [0.0|1] ""  ZR_High
 SG_ HBFS_TAG_betaetigt : 8|1@1+ (1.0,0.0) [0.0|1] ""  ZR_High
 SG_ HBFS_TIG_betaetigt : 9|1@1+ (1.0,0.0) [0.0|1] ""  ZR_High
 SG_ HBFS_FH_S_HFS_AutoHoch : 10|1@1+ (1.0,0.0) [0.0|1] ""  ZR_High
 SG_ HBFS_FH_S_HFS_AutoTief : 11|1@1+ (1.0,0.0) [0.0|1] ""  ZR_High
 SG_ HBFS_FH_S_HFS_ManHoch : 12|1@1+ (1.0,0.0) [0.0|1] ""  ZR_High
 SG_ HBFS_FH_S_HFS_ManTief : 13|1@1+ (1.0,0.0) [0.0|1] ""  ZR_High
 SG_ HBFS_Tuer_Status : 14|2@1+ (1.0,0.0) [0.0|3] ""  OTA_FC,ZR_High
 SG_ HBFS_SAD_Schalter : 16|4@1+ (1.0,0.0) [0.0|15] ""  ZR_High
 SG_ HBFS_FH_S_ManHoch : 20|1@1+ (1.0,0.0) [0.0|1] ""  ZR_High
 SG_ HBFS_FH_S_AutoHoch : 21|1@1+ (1.0,0.0) [0.0|1] ""  ZR_High
 SG_ HBFS_FH_S_ManTief : 22|1@1+ (1.0,0.0) [0.0|1] ""  ZR_High
 SG_ HBFS_FH_S_AutoTief : 23|1@1+ (1.0,0.0) [0.0|1] ""  ZR_High
 SG_ HBFS_FH_Oeffnung : 24|8@1+ (0.5,0) [0.0|100.0] "Unit_PerCent"  DDA,OTA_FC,ZR_High,ZR_LIMU,ZR_MIB_TOP_ab_Gen3,ZR_Standard
 SG_ HBFS_FH_Bew_hoch : 32|1@1+ (1.0,0.0) [0.0|1] ""  ZR_High
 SG_ HBFS_FH_Bew_tief : 33|1@1+ (1.0,0.0) [0.0|1] ""  ZR_High
 SG_ HBFS_FH_Fang : 34|1@1+ (1.0,0.0) [0.0|1] ""  Vector__XXX
 SG_ HBFS_FH_Block : 35|1@1+ (1.0,0.0) [0.0|1] ""  ZR_High
 SG_ HBFS_FH_Thermo : 36|1@1+ (1.0,0.0) [0.0|1] ""  ZR_High
 SG_ HBFS_UEKB_aktiviert : 37|1@1+ (1.0,0.0) [0.0|1] ""  ZR_High
 SG_ HBFS_Tueroeffnen_Warnung : 38|1@1+ (1.0,0.0) [0.0|1] ""  Vector__XXX
 SG_ HBFS_FH_normiert : 39|1@1+ (1.0,0.0) [0.0|1] ""  BedienSG_hi,ZR_High
 SG_ ASW_Warnung_aktiv_HBFS : 40|1@1+ (1.0,0.0) [0.0|1] ""  ZR_High
 SG_ HBFS_Zuziehhilfe_aktiv : 41|1@1+ (1.0,0.0) [0.0|1] ""  OTA_FC,ZR_High
 SG_ HBFS_Seitenrollo_hoch : 42|1@1+ (1.0,0.0) [0.0|1] ""  BedienSG_hi,ZR_High
 SG_ HBFS_Seitenrollo_tief : 43|1@1+ (1.0,0.0) [0.0|1] ""  BedienSG_hi,ZR_High
 SG_ HBFS_Status_KiSi : 44|1@1+ (1.0,0.0) [0.0|1] ""  BedienSG_hi,ZR_High
 SG_ SSR_HBFS_Pos_Unten : 45|1@1+ (1.0,0.0) [0.0|1] ""  ZR_High
 SG_ HBFS_Oben_Block_erw : 46|1@1+ (1.0,0.0) [0.0|1] ""  ZR_High
 SG_ HBFS_Unten_Block_erw : 47|1@1+ (1.0,0.0) [0.0|1] ""  ZR_High
 SG_ MTHBFS_M_Taste : 48|1@1+ (1.0,0.0) [0.0|1] ""  ZR_High
 SG_ MTHBFS_Pos1 : 49|1@1+ (1.0,0.0) [0.0|1] ""  ZR_High
 SG_ MTHBFS_Pos2 : 50|1@1+ (1.0,0.0) [0.0|1] ""  ZR_High
 SG_ MTHBFS_Pos3 : 51|1@1+ (1.0,0.0) [0.0|1] ""  ZR_High
 SG_ HBFS_MRollo_Schalter : 52|3@1+ (1.0,0.0) [0.0|7] ""  ZR_High
 SG_ HBFS_Lock_Taster_inv : 55|1@1+ (1.0,0.0) [0.0|1] ""  ZR_High
 SG_ HBFS_Status_KiSi_inv : 56|1@1+ (1.0,0.0) [0.0|1] ""  ZR_High
 SG_ HBFS_Status_eTAG : 57|2@1+ (1.0,0.0) [0.0|3] ""  Vector__XXX
 SG_ HBFS_Tuer_Status_QBit : 59|1@1+ (1.0,0.0) [0.0|1] ""  Vector__XXX
 SG_ HBFS_TIG_betaetigt_schliessen : 60|1@1+ (1.0,0.0) [0.0|1] ""  Vector__XXX

BO_ 974 TSG_HFS_01: 8 Gateway
 SG_ HFS_Tuer_geoeffnet : 0|1@1+ (1.0,0.0) [0.0|1] ""  OTA_FC,ZR_High,ZR_LIMU,ZR_MIB_TOP_ab_Gen3,ZR_Standard
 SG_ HFS_verriegelt : 1|1@1+ (1.0,0.0) [0.0|1] ""  ZR_High
 SG_ HFS_gesafet : 2|1@1+ (1.0,0.0) [0.0|1] ""  ZR_High
 SG_ HFS_Heckrollotaster_betaetigt : 3|1@1+ (1.0,0.0) [0.0|1] ""  ZR_High
 SG_ HFS_Tuerschloss_defekt : 4|1@1+ (1.0,0.0) [0.0|1] ""  ZR_High
 SG_ HFS_Unlock_Taster : 5|1@1+ (1.0,0.0) [0.0|1] ""  ZR_High
 SG_ HFS_Lock_Taster : 6|1@1+ (1.0,0.0) [0.0|1] ""  ZR_High
 SG_ HFS_Sperrklinke : 7|1@1+ (1.0,0.0) [0.0|1] ""  ZR_High
 SG_ HFS_TAG_betaetigt : 8|1@1+ (1.0,0.0) [0.0|1] ""  ZR_High
 SG_ HFS_TIG_betaetigt : 9|1@1+ (1.0,0.0) [0.0|1] ""  ZR_High
 SG_ HFS_FH_S_HBFS_AutoHoch : 10|1@1+ (1.0,0.0) [0.0|1] ""  ZR_High
 SG_ HFS_FH_S_HBFS_AutoTief : 11|1@1+ (1.0,0.0) [0.0|1] ""  ZR_High
 SG_ HFS_FH_S_HBFS_ManHoch : 12|1@1+ (1.0,0.0) [0.0|1] ""  ZR_High
 SG_ HFS_FH_S_HBFS_ManTief : 13|1@1+ (1.0,0.0) [0.0|1] ""  ZR_High
 SG_ HFS_Tuer_Status : 14|2@1+ (1.0,0.0) [0.0|3] ""  OTA_FC,ZR_High
 SG_ HFS_SAD_Schalter : 16|4@1+ (1.0,0.0) [0.0|15] ""  ZR_High
 SG_ HFS_FH_S_ManHoch : 20|1@1+ (1.0,0.0) [0.0|1] ""  ZR_High
 SG_ HFS_FH_S_AutoHoch : 21|1@1+ (1.0,0.0) [0.0|1] ""  ZR_High
 SG_ HFS_FH_S_ManTief : 22|1@1+ (1.0,0.0) [0.0|1] ""  ZR_High
 SG_ HFS_FH_S_AutoTief : 23|1@1+ (1.0,0.0) [0.0|1] ""  ZR_High
 SG_ HFS_FH_Oeffnung : 24|8@1+ (0.5,0) [0.0|100.0] "Unit_PerCent"  DDA,OTA_FC,ZR_High,ZR_LIMU,ZR_MIB_TOP_ab_Gen3,ZR_Standard
 SG_ HFS_FH_Bew_hoch : 32|1@1+ (1.0,0.0) [0.0|1] ""  ZR_High
 SG_ HFS_FH_Bew_tief : 33|1@1+ (1.0,0.0) [0.0|1] ""  ZR_High
 SG_ HFS_FH_Fang : 34|1@1+ (1.0,0.0) [0.0|1] ""  ZR_High
 SG_ HFS_FH_Block : 35|1@1+ (1.0,0.0) [0.0|1] ""  ZR_High
 SG_ HFS_FH_Thermo : 36|1@1+ (1.0,0.0) [0.0|1] ""  ZR_High
 SG_ HFS_UEKB_aktiviert : 37|1@1+ (1.0,0.0) [0.0|1] ""  ZR_High
 SG_ HFS_Tueroeffnen_Warnung : 38|1@1+ (1.0,0.0) [0.0|1] ""  Vector__XXX
 SG_ HFS_FH_normiert : 39|1@1+ (1.0,0.0) [0.0|1] ""  BedienSG_hi,ZR_High
 SG_ ASW_Warnung_aktiv_HFS : 40|1@1+ (1.0,0.0) [0.0|1] ""  ZR_High
 SG_ HFS_Zuziehhilfe_aktiv : 41|1@1+ (1.0,0.0) [0.0|1] ""  OTA_FC,ZR_High
 SG_ HFS_Seitenrollo_hoch : 42|1@1+ (1.0,0.0) [0.0|1] ""  BedienSG_hi,ZR_High
 SG_ HFS_Seitenrollo_tief : 43|1@1+ (1.0,0.0) [0.0|1] ""  BedienSG_hi,ZR_High
 SG_ HFS_Status_KiSi : 44|1@1+ (1.0,0.0) [0.0|1] ""  BedienSG_hi,ZR_High
 SG_ SSR_HFS_Pos_Unten : 45|1@1+ (1.0,0.0) [0.0|1] ""  ZR_High
 SG_ HFS_Oben_Block_erw : 46|1@1+ (1.0,0.0) [0.0|1] ""  ZR_High
 SG_ HFS_Unten_Block_erw : 47|1@1+ (1.0,0.0) [0.0|1] ""  ZR_High
 SG_ MTHFS_M_Taste : 48|1@1+ (1.0,0.0) [0.0|1] ""  ZR_High
 SG_ MTHFS_Pos1 : 49|1@1+ (1.0,0.0) [0.0|1] ""  ZR_High
 SG_ MTHFS_Pos2 : 50|1@1+ (1.0,0.0) [0.0|1] ""  ZR_High
 SG_ MTHFS_Pos3 : 51|1@1+ (1.0,0.0) [0.0|1] ""  ZR_High
 SG_ HFS_MRollo_Schalter : 52|3@1+ (1.0,0.0) [0.0|7] ""  ZR_High
 SG_ HFS_Lock_Taster_inv : 55|1@1+ (1.0,0.0) [0.0|1] ""  ZR_High
 SG_ HFS_Status_eTAG : 56|2@1+ (1.0,0.0) [0.0|3] ""  Vector__XXX
 SG_ HFS_Tuer_Status_QBit : 58|1@1+ (1.0,0.0) [0.0|1] ""  Vector__XXX
 SG_ HFS_TCR_Mode_aktiv : 59|1@1+ (1.0,0.0) [0.0|1] ""  Vector__XXX

BO_ 960 Klemmen_Status_01: 4 Gateway
 SG_ ZAS_Kl_15a : 16|1@1+ (1.0,0.0) [0.0|1] ""  XXX
 SG_ ZAS_Kl_15b : 17|1@1+ (1.0,0.0) [0.0|1] ""  XXX
 SG_ ZAS_Kl_15c : 18|1@1+ (1.0,0.0) [0.0|1] ""  XXX
